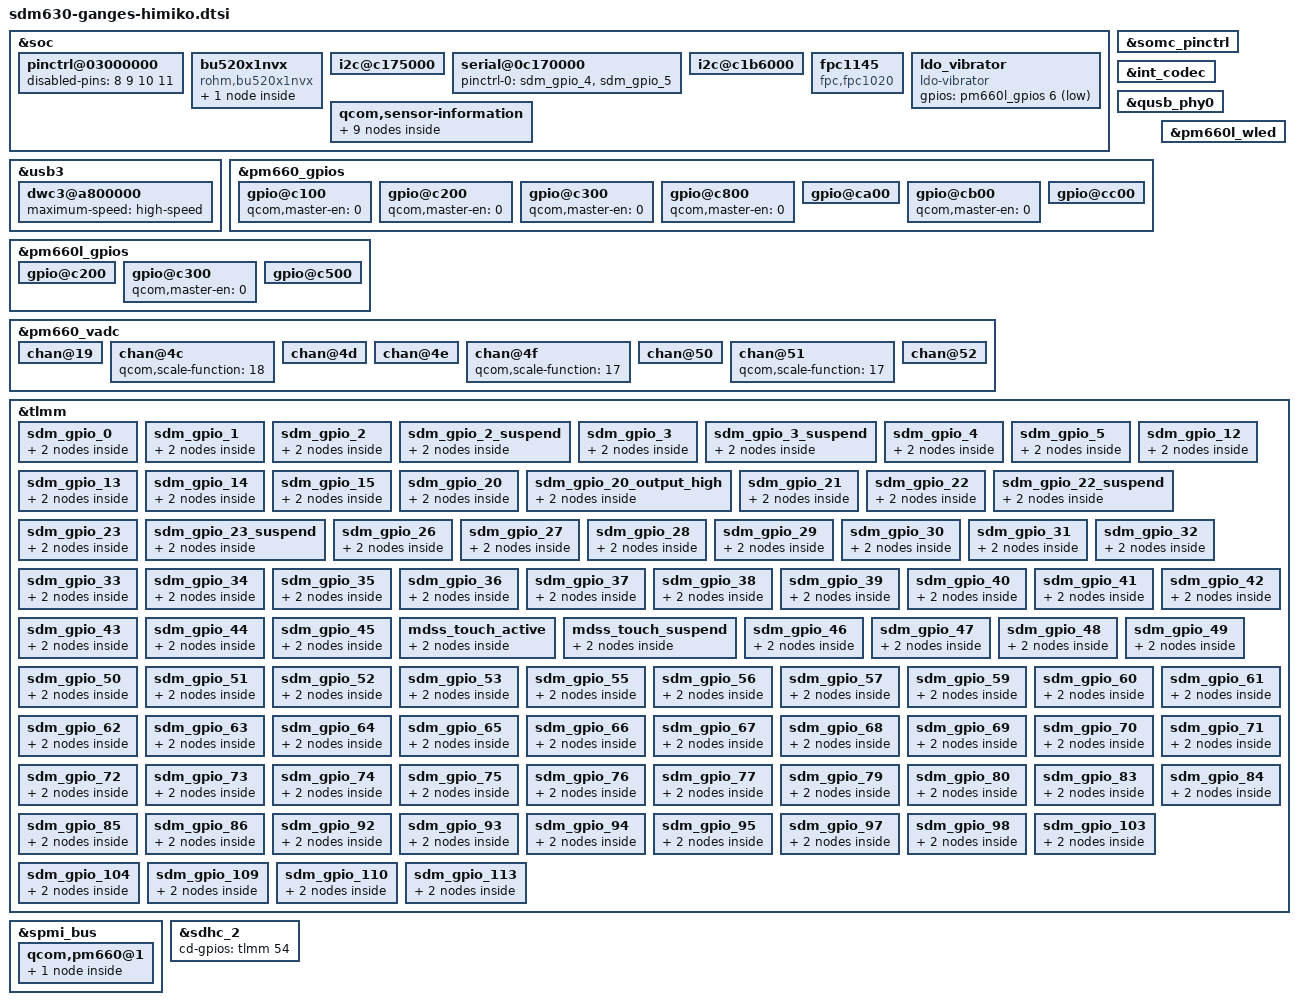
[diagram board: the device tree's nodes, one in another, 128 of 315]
/* arch/arm64/boot/dts/somc/sdm630-ganges-mermaid.dtsi
 *
 * This program is free software; you can redistribute it and/or modify
 * it under the terms of the GNU General Public License version 2 and
 * only version 2 as published by the Free Software Foundation.
 *
 * This program is distributed in the hope that it will be useful,
 * but WITHOUT ANY WARRANTY; without even the implied warranty of
 * MERCHANTABILITY or FITNESS FOR A PARTICULAR PURPOSE.  See the
 * GNU General Public License for more details.
*/
/*
 * Copyright (C) 2018 Sony Mobile Communications Inc.
 *
 * This program is free software; you can redistribute it and/or modify
 * it under the terms of the GNU General Public License version 2, as
 * published by the Free Software Foundation.
 */

#include "sdm630-ganges-common.dtsi"
//#include "sdm630-ganges-mermaid-camera-sensor.dtsi"
#include "sdm630-ganges-himiko-camera-sensor.dtsi"
#include "somc-ganges-nfc_pn81t.dtsi"
#include "dsi-panel-himiko.dtsi"
#include "sdm630-ganges-touch_himiko.dtsi"
#include <dt-bindings/gpio/gpio.h>
#include "charger-ganges-himiko.dtsi"

&soc {
	pinctrl@03000000 {
		disabled-pins = <8 9 10 11>;
	};

	bu520x1nvx {
		compatible = "rohm,bu520x1nvx";

		acc_cover {
			label = "lid";
			gpios = <&tlmm 75 0x1>;
			lid-pin = <1>;
			open-debounce-interval = <120>;
			close-debounce-interval = <300>;
		};
	};

	/* I2C : BLSP1 */
	i2c@c175000 { /* BLSP1 QUP1 */
		pinctrl-0 = <&sdm_gpio_2 &sdm_gpio_3>;
		pinctrl-1 = <&sdm_gpio_2_suspend &sdm_gpio_3_suspend>;
		qcom,clk-freq-out = <400000>;
		status = "okay";
	};

	/* UART : BLSP2 */
	serial@0c170000 {
		pinctrl-0 = <&sdm_gpio_4 &sdm_gpio_5>;
		status = "okay";
	};

	/* I2C : BLSP6 */
	i2c@c1b6000 { /* BLSP2 QUP2 */
		pinctrl-0 = <&sdm_gpio_22 &sdm_gpio_23>;
		pinctrl-1 = <&sdm_gpio_22_suspend &sdm_gpio_23_suspend>;
		qcom,clk-freq-out = <400000>;
		status = "okay";
	};

	fpc1145 {
		status = "ok";
		compatible = "fpc,fpc1020", "fpc1145";
		interrupt-parent = <&tlmm>;
		interrupts = <72 0x0>;
		fpc,gpio_rst    = <&tlmm 20 0x0>;
		fpc,gpio_irq    = <&tlmm 72 0x0>;
		vdd_ana-supply  = <&pm660l_bob>;
		vdd_ana-min-uV  = <3300000>;
		vdd_ana-max-uV  = <3600000>;

		gpio_ldo_enabe = <&pm660l_gpios 3 0x00>;
		pinctrl-names = "fpc1145_reset_reset",
				"fpc1145_reset_active",
				"fpc1145_irq_active";

		pinctrl-0 = <&sdm_gpio_20>;
		pinctrl-1 = <&sdm_gpio_20_output_high>;
		pinctrl-2 = <&sdm_gpio_72>;
	};

	ldo_vibrator {
		compatible = "ldo-vibrator";
		gpios = <&pm660l_gpios 6 1>;
	};
	qcom,sensor-information {
			/* msm_therm */
			sensor_information13: qcom,sensor-information-13 {
				qcom,scaling-factor = <1000>;
			};

			/* xo_therm */
			sensor_information14: qcom,sensor-information-14 {
				qcom,scaling-factor = <1000>;
			};

			/* pa_therm0 */
			sensor_information15: qcom,sensor-information-15 {
				qcom,scaling-factor = <1000>;
			};

			/* pa_therm1 */
			sensor_information16: qcom,sensor-information-16 {
				qcom,scaling-factor = <1000>;
			};

			/* quiet_therm */
			sensor_information17: qcom,sensor-information-17 {
				qcom,scaling-factor = <1000>;
				qcom,alias-name = "bl_therm";
			};

			/* sdm_therm */
			sensor_information100: qcom,sensor-information-100 {
				qcom,sensor-type = "adc";
				qcom,scaling-factor = <1000>;
				qcom,sensor-name = "sdm_therm";
			};

			/* emcp_therm */
			sensor_information101: qcom,sensor-information-101 {
				qcom,sensor-type = "adc";
				qcom,scaling-factor = <1000>;
				qcom,sensor-name = "emcp_therm";
			};

			/* flash_therm */
			sensor_information102: qcom,sensor-information-102 {
				qcom,sensor-type = "adc";
				qcom,sensor-name = "flash_therm";
				qcom,scaling-factor = <1000>;
			};

			/* bms */
			sensor_information103: qcom,sensor-information-103 {
				qcom,sensor-type = "adc";
				qcom,sensor-name = "bms";
				qcom,scaling-factor = <1000>;
				qcom,alias-name = "batt_therm";
			};
		};
};

&somc_pinctrl {
	/* If variant specific default setting is needed,
	fill pinctrl-2 value in <variant>.dtsi */
	pinctrl-2 = <&sdm_gpio_0 &sdm_gpio_1 &sdm_gpio_2 &sdm_gpio_3
			 &sdm_gpio_12 &sdm_gpio_13
			 &sdm_gpio_14 &sdm_gpio_15 &sdm_gpio_20 &sdm_gpio_21 &sdm_gpio_22
			 &sdm_gpio_23 &sdm_gpio_26 &sdm_gpio_27 &sdm_gpio_28 &sdm_gpio_29
			 &sdm_gpio_30 &sdm_gpio_31 &sdm_gpio_32 &sdm_gpio_33 &sdm_gpio_34
			 &sdm_gpio_35 &sdm_gpio_36 &sdm_gpio_37 &sdm_gpio_38 &sdm_gpio_39
			 &sdm_gpio_40 &sdm_gpio_41 &sdm_gpio_42 &sdm_gpio_43 &sdm_gpio_44
			 &sdm_gpio_45 &sdm_gpio_46 &sdm_gpio_47 &sdm_gpio_48 &sdm_gpio_49
			 &sdm_gpio_50 &sdm_gpio_51 &sdm_gpio_52 /*&sdm_gpio_53*/
			 &sdm_gpio_55 &sdm_gpio_56 &sdm_gpio_57 /*&sdm_gpio_59*/ &sdm_gpio_60
			 &sdm_gpio_61 &sdm_gpio_62 &sdm_gpio_63 &sdm_gpio_64 &sdm_gpio_65
			 &sdm_gpio_66 &sdm_gpio_67 &sdm_gpio_68 &sdm_gpio_69 &sdm_gpio_70
			 &sdm_gpio_71 &sdm_gpio_72 &sdm_gpio_73 &sdm_gpio_74 &sdm_gpio_75
			 &sdm_gpio_76 &sdm_gpio_77 &sdm_gpio_79 &sdm_gpio_80
			 &sdm_gpio_83 &sdm_gpio_84 &sdm_gpio_85 &sdm_gpio_86
			 /*&sdm_gpio_90*/ &sdm_gpio_92 &sdm_gpio_93 &sdm_gpio_94 &sdm_gpio_95
			 &sdm_gpio_97 &sdm_gpio_98 &sdm_gpio_103 &sdm_gpio_104
			 &sdm_gpio_109 &sdm_gpio_110 &sdm_gpio_113>;
};

&int_codec {
	qcom,msm-micbias1-ext-cap;
	/delete-property/ qcom,msm-micbias2-ext-cap;
	qcom,msm-hs-micbias-type = "external";
	qcom,audio-routing =
		"RX_BIAS", "INT_MCLK0",
		"SPK_RX_BIAS", "INT_MCLK0",
		"INT_LDO_H", "INT_MCLK0",
		"RX_I2S_CLK", "INT_MCLK0",
		"TX_I2S_CLK", "INT_MCLK0",
		"MIC BIAS External", "Handset Mic",
		"MIC BIAS External2", "Headset Mic",
		"MIC BIAS External", "Secondary Mic",
		"AMIC1", "MIC BIAS External",
		"AMIC2", "MIC BIAS External2",
		"AMIC3", "MIC BIAS External",
		"DMIC1", "MIC BIAS External",
		"MIC BIAS External", "Digital Mic1",
		"DMIC2", "MIC BIAS External",
		"MIC BIAS External", "Digital Mic2",
		"DMIC3", "MIC BIAS External",
		"MIC BIAS External", "Digital Mic3",
		"DMIC4", "MIC BIAS External",
		"MIC BIAS External", "Digital Mic4",
		"SpkrLeft IN", "SPK1 OUT",
		"SpkrRight IN", "SPK2 OUT",
		"PDM_IN_RX1", "PDM_OUT_RX1",
		"PDM_IN_RX2", "PDM_OUT_RX2",
		"PDM_IN_RX3", "PDM_OUT_RX3",
		"ADC1_IN", "ADC1_OUT",
		"ADC2_IN", "ADC2_OUT",
		"ADC3_IN", "ADC3_OUT";
};

&qusb_phy0 {
	qcom,tune2-efuse-correction = <0>;
	qcom,qusb-phy-init-seq = <0xf8 0x80
			0xd3 0x84
			0x83 0x88
			0xc7 0x8c
			0x30 0x08
			0x79 0x0c
			0x21 0x10
			0x14 0x9c
			0x9f 0x1c
			0x00 0x18>;
};

&usb3 {
	dwc3@a800000 {
		maximum-speed = "high-speed";
	};
};

&pm660_gpios {
	/* GPIO_1: PON_OPTION_1 */
	/* Follow QTI */

	/* GPIO_2: FLASH_THERM */
	gpio@c100 {
		qcom,master-en = <0>;           /* Disable */
		status = "okay";
	};

	/* GPIO_3: LCD_ID */
	gpio@c200 {
		qcom,master-en = <0>;           /* Disable */
		status = "okay";
	};

	/* GPIO_4: NFC_CLK_REQ */
	gpio@c300 {
		qcom,master-en = <0>;           /* Disable */
		status = "okay";
	};

	/* GPIO_5: WLAN_SW_CTRL */
	/* Follow QTI */

	/* GPIO_6: PMK_SLEEP_CLK */
	/* Follow QTI */

	/* GPIO_7: BUA */
	/* Follow QTI */

	/* GPIO_8: SLB */
	/* Follow QTI */

	/* GPIO_9: NC */
	gpio@c800 {
		qcom,master-en = <0>;           /* Disable */
		status = "okay";
	};

	/* GPIO_10: WCSS_PWR_REQ */
	/* Follow QTI */

	/* GPIO_11: RF_ID_0 */
	gpio@ca00 {
		qcom,src-sel = <0>;             /* GPIO */
		qcom,mode = <0>;                /* In */
		qcom,vin-sel = <0>;             /* 1.8V */
		qcom,pull = <4>;		/* PD */
		qcom,master-en = <1>;           /* Enable */
		status = "ok";
	};

	/* GPIO_12: USB_DETECT_ADC */
	gpio@cb00 {
		qcom,master-en = <0>;           /* Disable */
		status = "okay";
	};

	/* GPIO_13: RF_ID_1 */
	gpio@cc00 {
		qcom,src-sel = <0>;             /* GPIO */
		qcom,mode = <0>;                /* In */
		qcom,vin-sel = <0>;             /* 1.8V */
		qcom,pull = <4>;		/* PD */
		qcom,master-en = <1>;           /* Enable */
		status = "ok";
	};
};

&pm660l_gpios {
	/* GPIO_1: GPIO_1B */
	/* Follow QTI */

	/* GPIO_2: LPI_PWR_EN */
	/* Follow QTI */

	/* GPIO_3: FP_LDO_EN */
	gpio@c200 {
		qcom,mode = <1>;                /* Output */
		qcom,pull = <5>;                /* No Pull */
		qcom,vin-sel = <0>;             /* VIN1 GPIO_LV */
		qcom,src-sel = <0>;             /* GPIO */
		qcom,master-en = <1>;           /* Enable GPIO */
		status = "ok";
	};

	/* GPIO_4: NC */
	gpio@c300 {
		qcom,master-en = <0>;           /* Disable */
		status = "okay";
	};

	/* GPIO_5: NC */
	/* Follow QTI */

	/* GPIO_6: VIB_LDO_EN */
	gpio@c500 {
		qcom,src-sel = <0>;             /* GPIO */
		qcom,mode = <1>;                /* Out */
		qcom,output-type = <0>;         /* CMOS */
		qcom,vin-sel = <0>;             /* 1.8V */
		qcom,out-strength = <1>;        /* Low */
		qcom,invert = <0>;              /* Low */
		qcom,master-en = <1>;           /* Enable */
		status = "okay";
	};

	/* GPIO_7: VOL_DN_S */
	/* Follow QTI */

	/* GPIO_8: NC */
	/* Follow QTI */

	/* GPIO_9: WCSS_PWR_REQ */
	/* Follow QTI */

	/* GPIO_10: SLB */
	/* Follow QTI */

	/* GPIO_11: LP4X_CTRL_BUCK_EN */
	/* Follow QTI */

	/* GPIO_12: LP4X_BUCK_MODE */
	/* Follow QTI */
};
&pm660_vadc {
	chan@19 { /* USB_DETECT_ADC */
		label = "usb_detect";
		reg = <0x19>;
		qcom,decimation = <0>;
		qcom,pre-div-channel-scaling = <0>;
		qcom,calibration-type = "absolute";
		qcom,scale-function = <0>;
		qcom,hw-settle-time = <5>;
		qcom,fast-avg-setup = <0>;
	};

	chan@4c { /* XO_THERM */
		qcom,scale-function = <18>;
	};

	chan@4d { /* Rename from msm_therm */
		label = "sdm_therm";
		qcom,scale-function = <17>;
		qcom,vadc-thermal-node;
	};

	chan@4e { /* Rename from emmc_therm */
		label = "emcp_therm";
		qcom,scale-function = <17>;
	};

	chan@4f { /* pa_therm0 */
		qcom,scale-function = <17>;
	};

	chan@50 {
		label = "pa_therm1";
		reg = <0x50>;
		qcom,decimation = <2>;
		qcom,pre-div-channel-scaling = <0>;
		qcom,calibration-type = "ratiometric";
		qcom,scale-function = <17>;
		qcom,hw-settle-time = <2>;
		qcom,fast-avg-setup = <0>;
		qcom,vadc-thermal-node;
	};

	chan@51 { /* quiet_therm */
		qcom,scale-function = <17>;
	};

	chan@52 {
		label = "flash_therm";
		reg = <0x52>;
		qcom,decimation = <2>;
		qcom,pre-div-channel-scaling = <0>;
		qcom,calibration-type = "ratiometric";
		qcom,scale-function = <17>;
		qcom,hw-settle-time = <2>;
		qcom,fast-avg-setup = <0>;
		qcom,vadc-thermal-node;
	};
};
&pm660l_wled {
	qcom,led-strings-list = [00 01 02];
	qcom,fs-curr-ua = <21000>;
	somc,calc-curr;
};

&tlmm {
	/* GPIO_0 : HWID_1 */
	sdm_gpio_0: sdm_gpio_0 {
		mux {
			pins = "gpio0";
			function = "gpio";
		};

		config {
			pins = "gpio0";
			drive-strength = <2>;
			bias-disable;
			input-enable;
		};
	};

	/* GPIO_1 : HWID_2 */
	sdm_gpio_1: sdm_gpio_1 {
		mux {
			pins = "gpio1";
			function = "gpio";
		};

		config {
			pins = "gpio1";
			drive-strength = <2>;
			bias-disable;
			input-enable;
		};
	};

	/* GPIO_2 : BLSP4_I2C_SDA */
	sdm_gpio_2: sdm_gpio_2 {
		mux {
			pins = "gpio2";
			function = "blsp_i2c1";
		};

		config {
			pins = "gpio2";
			drive-strength = <2>;
			bias-disable;
		};
	};

	/* GPIO_2 : BLSP4_I2C_SDA (Suspend) */
	sdm_gpio_2_suspend: sdm_gpio_2_suspend {
		mux {
			pins = "gpio2";
			function = "gpio";
		};

		config {
			pins = "gpio2";
			drive-strength = <2>;
			bias-disable;
			input-enable;
		};
	};

	/* GPIO_3 : BLSP1_I2C_SCL */
	sdm_gpio_3: sdm_gpio_3 {
		mux {
			pins = "gpio3";
			function = "blsp_i2c1";
		};

		config {
			pins = "gpio3";
			drive-strength = <2>;
			bias-disable;
		};
	};

	/* GPIO_3 : BLSP1_I2C_SCL (Suspend) */
	sdm_gpio_3_suspend: sdm_gpio_3_suspend {
		mux {
			pins = "gpio3";
			function = "gpio";
		};

		config {
			pins = "gpio3";
			drive-strength = <2>;
			bias-disable;
			input-enable;
		};
	};

	/* GPIO_4 : BLSP2_UART_TX */
	sdm_gpio_4: sdm_gpio_4 {
		mux {
			pins = "gpio4";
			function = "blsp_uart2";
		};

		config {
			pins = "gpio4";
			drive-strength = <4>;
			bias-disable;
		};
	};

	/* GPIO_5 : BLSP2_UART_RX */
	sdm_gpio_5: sdm_gpio_5 {
		mux {
			pins = "gpio5";
			function = "blsp_uart2";
		};

		config {
			pins = "gpio5";
			drive-strength = <2>;
			bias-pull-up;
		};
	};

	/* GPIO_6 : BLSP2_I2C_SDA */
	/* Follow QTI */

	/* GPIO_7 : BLSP2_I2C_SCL */
	/* Follow QTI */

	/* GPIO_12 : NFC_ESE_SPI_MOSI */
	sdm_gpio_12: sdm_gpio_12 {
		mux {
			pins = "gpio12";
			function = "blsp_spi4";
		};

		config {
			pins = "gpio12";
			drive-strength = <6>;
			bias-pull-down;
		};
	};

	/* GPIO_13 : NFC_ESE_SPI_MISO */
	sdm_gpio_13: sdm_gpio_13 {
		mux {
			pins = "gpio13";
			function = "blsp_spi4";
		};

		config {
			pins = "gpio13";
			drive-strength = <2>;
			bias-disable;
		};
	};

	/* GPIO_14 : NFC_ESE_SPI_CS_N */
	sdm_gpio_14: sdm_gpio_14 {
		mux {
			pins = "gpio14";
			function = "gpio";
		};

		config {
			pins = "gpio14";
			drive-strength = <2>;
			bias-disable;
			output-low;
		};
	};

	/* GPIO_15 : NFC_ESE_SPI_SCLK */
	sdm_gpio_15: sdm_gpio_15 {
		mux {
			pins = "gpio15";
			function = "blsp_spi4";
		};

		config {
			pins = "gpio15";
			drive-strength = <6>;
			bias-pull-down;
		};
	};

	/* GPIO_16 : BLSP5_HCI_UART_TX */
	/* Follow QTI */

	/* GPIO_17 : BLSP5_HCI_UART_RX */
	/* Follow QTI */

	/* GPIO_18 : BLSP5_HCI_UART_CTS_N */
	/* Follow QTI */

	/* GPIO_19 : BLSP5_HCI_UART_RFR_N */
	/* Follow QTI */

	/* GPIO_20 : FP_RESET_N */
	sdm_gpio_20: sdm_gpio_20 {
		mux {
			pins = "gpio20";
			function = "gpio";
		};

		config {
			pins = "gpio20";
			drive-strength = <2>;
			bias-disable;
			output-low;
		};
	};

	/* GPIO_20 : FP_RESET_N, state device active */
	sdm_gpio_20_output_high: sdm_gpio_20_output_high {
		mux {
			pins = "gpio20";
			function = "gpio";
		};

		config {
			pins = "gpio20";
			drive-strength = <2>;
			bias-disable;
			output-high;
		};
	};

	/* GPIO_21 : SUBC_AFVDD_EN */
	sdm_gpio_21: sdm_gpio_21 {
		mux {
			pins = "gpio21";
			function = "gpio";
		};

		config {
			pins = "gpio21";
			drive-strength = <2>;
			bias-disable;
			output-low;
		};
	};

	/* GPIO_22 : BLSP6_I2C_SDA */
	sdm_gpio_22: sdm_gpio_22 {
		mux {
			pins = "gpio22";
			function = "blsp_i2c6";
		};

		config {
			pins = "gpio22";
			drive-strength = <2>;
			bias-disable;
		};
	};

	/* GPIO_22 : BLSP6_I2C_SDA (Suspend) */
	sdm_gpio_22_suspend: sdm_gpio_22_suspend {
		mux {
			pins = "gpio22";
			function = "gpio";
		};

		config {
			pins = "gpio22";
			drive-strength = <2>;
			bias-pull-up;
			input-enable;
		};
	};

	/* GPIO_23 : BLSP6_I2C_SCL */
	sdm_gpio_23: sdm_gpio_23 {
		mux {
			pins = "gpio23";
			function = "blsp_i2c6";
		};

		config {
			pins = "gpio23";
			drive-strength = <2>;
			bias-disable;
		};
	};

	/* GPIO_23 : BLSP6_I2C_SCL (Suspend) */
	sdm_gpio_23_suspend: sdm_gpio_23_suspend {
		mux {
			pins = "gpio23";
			function = "gpio";
		};

		config {
			pins = "gpio23";
			drive-strength = <2>;
			bias-pull-up;
			input-enable;
		};
	};

	/* GPIO_24 : SDM_SWR_CLK */
	/* Follow QTI */

	/* GPIO_25 : SDM_SWR_DATA */
	/* Follow QTI */

	/* GPIO_26 : WSA_EN */
	sdm_gpio_26: sdm_gpio_26 {
		mux {
			pins = "gpio26";
			function = "gpio";
		};

		config {
			pins = "gpio26";
			drive-strength = <2>;
			bias-disable;
			output-low;
		};
	};

	/* GPIO_27 : NC */
	sdm_gpio_27: sdm_gpio_27 {
		mux {
			pins = "gpio27";
			function = "gpio";
		};

		config {
			pins = "gpio27";
			drive-strength = <2>;
			bias-pull-down;
			input-enable;
		};
	};

	/* GPIO_28 : NFC_IRQ */
	sdm_gpio_28: sdm_gpio_28 {
		mux {
			pins = "gpio28";
			function = "gpio";
		};

		config {
			pins = "gpio28";
			drive-strength = <2>;
			bias-pull-down;
			input-enable;
		};
	};

	/* GPIO_29 : NFC_EN */
	sdm_gpio_29: sdm_gpio_29 {
		mux {
			pins = "gpio29";
			function = "gpio";
		};

		config {
			pins = "gpio29";
			drive-strength = <2>;
			bias-disable;
			output-low;
		};
	};

	/* GPIO_30 : NFC_DWL_REQ */
	sdm_gpio_30: sdm_gpio_30 {
		mux {
			pins = "gpio30";
			function = "gpio";
		};

		config {
			pins = "gpio30";
			drive-strength = <2>;
			bias-disable;
			output-low;
		};
	};

	/* GPIO_31 : NFC_ESE_PWR_REQ */
	sdm_gpio_31: sdm_gpio_31 {
		mux {
			pins = "gpio31";
			function = "gpio";
		};

		config {
			pins = "gpio31";
			drive-strength = <2>;
			bias-disable;
			output-low;
		};
	};

	/* GPIO_32 : CAM0_MCLK */
	sdm_gpio_32: sdm_gpio_32 {
		mux {
			pins = "gpio32";
			function = "cam_mclk";
		};

		config {
			pins = "gpio32";
			drive-strength = <2>;
			bias-disable;
		};
	};

	/* GPIO_33 : CAM2_MCLK */
	sdm_gpio_33: sdm_gpio_33 {
		mux {
			pins = "gpio33";
			function = "cam_mclk";
		};

		config {
			pins = "gpio33";
			drive-strength = <2>;
			bias-disable;
		};
	};

	/* GPIO_34 : T2_MODE */
	sdm_gpio_34: sdm_gpio_34 {
		mux {
			pins = "gpio34";
			function = "gpio";
		};

		config {
			pins = "gpio34";
			drive-strength = <2>;
			bias-disable;
			output-low;
		};
	};

	/* GPIO_35 : CAM1_MCLK */
	sdm_gpio_35: sdm_gpio_35 {
		mux {
			pins = "gpio35";
			function = "cam_mclk";
		};

		config {
			pins = "gpio35";
			drive-strength = <2>;
			bias-disable;
			output-low;
		};
	};

	/* GPIO_36 : CCI_I2C_SDA0 */
	sdm_gpio_36: sdm_gpio_36 {
		mux {
			pins = "gpio36";
			function = "cci_i2c";
		};

		config {
			pins = "gpio36";
			drive-strength = <2>;
			bias-disable;
		};
	};

	/* GPIO_37 : CCI_I2C_SCL0 */
	sdm_gpio_37: sdm_gpio_37 {
		mux {
			pins = "gpio37";
			function = "cci_i2c";
		};

		config {
			pins = "gpio37";
			drive-strength = <2>;
			bias-disable;
		};
	};

	/* GPIO_38 : CCI_I2C_SDA1 */
	sdm_gpio_38: sdm_gpio_38 {
		mux {
			pins = "gpio38";
			function = "cci_i2c";
		};

		config {
			pins = "gpio38";
			drive-strength = <2>;
			bias-disable;
		};
	};

	/* GPIO_39 : CCI_I2C_SCL1 */
	sdm_gpio_39: sdm_gpio_39 {
		mux {
			pins = "gpio39";
			function = "cci_i2c";
		};

		config {
			pins = "gpio39";
			drive-strength = <2>;
			bias-disable;
		};
	};

	/* GPIO_40 : MAIN_DVDD_EN */
	sdm_gpio_40: sdm_gpio_40 {
		mux {
			pins = "gpio40";
			function = "gpio";
		};

		config {
			pins = "gpio40";
			drive-strength = <2>;
			bias-disable;
			output-low;
		};
	};

	/* GPIO_41 : FL_STROBE_TRIG */
	sdm_gpio_41: sdm_gpio_41 {
		mux {
			pins = "gpio41";
			function = "gpio";
		};

		config {
			pins = "gpio41";
			drive-strength = <2>;
			bias-disable;
			output-low;
		};
	};

	/* GPIO_42 : CAM1_RST_N */
	sdm_gpio_42: sdm_gpio_42 {
		mux {
			pins = "gpio42";
			function = "gpio";
		};

		config {
			pins = "gpio42";
			drive-strength = <2>;
			bias-disable;
			output-low;
		};
	};

	/* GPIO_43 : NC */
	sdm_gpio_43: sdm_gpio_43 {
		mux {
			pins = "gpio43";
			function = "gpio";
		};

		config {
			pins = "gpio43";
			drive-strength = <2>;
			bias-pull-down;
			input-enable;
		};
	};

	/* GPIO_44 : SUB_8M_ID */
	sdm_gpio_44: sdm_gpio_44 {
		mux {
			pins = "gpio44";
			function = "gpio";
		};

		config {
			pins = "gpio44";
			drive-strength = <2>;
			bias-disable;
			output-low;
		};
	};

	/* GPIO_45 : TS_INT_N */
	sdm_gpio_45: sdm_gpio_45 {
		mux {
			pins = "gpio45";
			function = "gpio";
		};

		config {
			pins = "gpio45";
			drive-strength = <2>;
			bias-pull-down;
			input-enable;
		};
	};

	mdss_touch_active: mdss_touch_active {
		mux {
			pins = "gpio45";
			function = "gpio";
		};

		config {
			pins = "gpio45";
			drive-strength = <2>;
			bias-pull-up;
		};
	};

	mdss_touch_suspend: mdss_touch_suspend {
		mux {
			pins = "gpio45";
			function = "gpio";
		};

		config {
			pins = "gpio45";
			drive-strength = <2>;
			bias-pull-down;
		};
	};

	/* GPIO_46 : CAM0_RST_N */
	sdm_gpio_46: sdm_gpio_46 {
		mux {
			pins = "gpio46";
			function = "gpio";
		};

		config {
			pins = "gpio46";
			drive-strength = <2>;
			bias-disable;
			output-low;
		};
	};

	/* GPIO_47 : CAM2_RST_N */
	sdm_gpio_47: sdm_gpio_47 {
		mux {
			pins = "gpio47";
			function = "gpio";
		};

		config {
			pins = "gpio47";
			drive-strength = <2>;
			bias-disable;
			output-low;
		};
	};

	/* GPIO_48 : SW_SERVICE */
	sdm_gpio_48: sdm_gpio_48 {
		mux {
			pins = "gpio48";
			function = "gpio";
		};

		config {
			pins = "gpio48";
			drive-strength = <2>;
			bias-pull-up;
			input-enable;
		};
	};

	/* GPIO_49 : FRONT_8M_ID */
	sdm_gpio_49: sdm_gpio_49 {
		mux {
			pins = "gpio49";
			function = "gpio";
		};

		config {
			pins = "gpio49";
			drive-strength = <2>;
			bias-disable;
			output-low;
		};
	};

	/* GPIO_50 : MAINC_AVDD_EN */
	sdm_gpio_50: sdm_gpio_50 {
		mux {
			pins = "gpio50";
			function = "gpio";
		};

		config {
			pins = "gpio50";
			drive-strength = <2>;
			bias-disable;
			output-low;
		};
	};

	/* GPIO_51 : SUBC_CHATC_AVDD_EN */
	sdm_gpio_51: sdm_gpio_51 {
		mux {
			pins = "gpio51";
			function = "gpio";
		};

		config {
			pins = "gpio51";
			drive-strength = <2>;
			bias-disable;
			output-low;
		};
	};

	/* GPIO_52 : SUBC_CHATC_DVDD_EN */
	sdm_gpio_52: sdm_gpio_52 {
		mux {
			pins = "gpio52";
			function = "gpio";
		};

		config {
			pins = "gpio52";
			drive-strength = <2>;
			bias-disable;
			output-low;
		};
	};

	/* GPIO_53 : LCD_RST_N */
	sdm_gpio_53: sdm_gpio_53 {
		mux {
			pins = "gpio53";
			function = "gpio";
		};

		config {
			pins = "gpio53";
			drive-strength = <2>;
			bias-disable;
		};
	};

	/* GPIO_54 : TRAY2_DET */
	/* Follow QTI */

	/* GPIO_55 : RF_LCD_ID_EN */
	sdm_gpio_55: sdm_gpio_55 {
		mux {
			pins = "gpio55";
			function = "gpio";
		};

		config {
			pins = "gpio55";
			drive-strength = <2>;
			bias-disable;
			output-low;
		};
	};

	/* GPIO_56 : NC */
	sdm_gpio_56: sdm_gpio_56 {
		mux {
			pins = "gpio56";
			function = "gpio";
		};

		config {
			pins = "gpio56";
			drive-strength = <2>;
			bias-pull-down;
			input-enable;
		};
	};

	/* GPIO_57 : FORCED_USB_BOOT */
	sdm_gpio_57: sdm_gpio_57 {
		mux {
			pins = "gpio57";
			function = "gpio";
		};

		config {
			pins = "gpio57";
			drive-strength = <2>;
			bias-pull-down;
			input-enable;
		};
	};

	/* GPIO_58 : USB_PHY_PS */
	/* Follow QTI */

	/* GPIO_59 : MDP_VSYNC_P */
	sdm_gpio_59: sdm_gpio_59 {
		mux {
			pins = "gpio59";
			function = "mdp_vsync";
		};

		config {
			pins = "gpio59";
			drive-strength = <2>;
			bias-disable;
		};
	};

	/* GPIO_60 : NC */
	sdm_gpio_60: sdm_gpio_60 {
		mux {
			pins = "gpio60";
			function = "gpio";
		};

		config {
			pins = "gpio60";
			drive-strength = <2>;
			bias-pull-down;
			input-enable;
		};
	};

	/* GPIO_61 : USB_DETECT_EN */
	sdm_gpio_61: sdm_gpio_61 {
		mux {
			pins = "gpio61";
			function = "gpio";
		};

		config {
			pins = "gpio61";
			drive-strength = <2>;
			bias-disable;
			output-low;
		};
	};

	/* GPIO_62 : DEBUG_GPIO0 */
	sdm_gpio_62: sdm_gpio_62 {
		mux {
			pins = "gpio62";
			function = "gpio";
		};

		config {
			pins = "gpio62";
			drive-strength = <2>;
			bias-disable;
			output-low;
		};
	};

	/* GPIO_63 : CAM_IO_EN */
	sdm_gpio_63: sdm_gpio_63 {
		mux {
			pins = "gpio63";
			function = "gpio";
		};

		config {
			pins = "gpio63";
			drive-strength = <2>;
			bias-disable;
			output-low;
		};
	};

	/* GPIO_64 : NC */
	sdm_gpio_64: sdm_gpio_64 {
		mux {
			pins = "gpio64";
			function = "gpio";
		};

		config {
			pins = "gpio64";
			drive-strength = <2>;
			bias-pull-down;
			input-enable;
		};
	};

	/* GPIO_65 : NC */
	sdm_gpio_65: sdm_gpio_65 {
		mux {
			pins = "gpio65";
			function = "gpio";
		};

		config {
			pins = "gpio65";
			drive-strength = <2>;
			bias-pull-down;
			input-enable;
		};
	};

	/* GPIO_66 : TS_RESET_N */
	sdm_gpio_66: sdm_gpio_66 {
		mux {
			pins = "gpio66";
			function = "gpio";
		};

		config {
			pins = "gpio66";
			drive-strength = <2>;
			bias-disable;
			output-low;
		};
	};

	/* GPIO_67 : PA_INDICATOR_IN */
	sdm_gpio_67: sdm_gpio_67 {
		mux {
			pins = "gpio67";
			function = "gpio";
		};

		config {
			pins = "gpio67";
			drive-strength = <2>;
			bias-disable;
			input-enable;
		};
	};

	/* GPIO_68 : ACCEL_INT */
	sdm_gpio_68: sdm_gpio_68 {
		mux {
			pins = "gpio68";
			function = "gpio";
		};

		config {
			pins = "gpio68";
			drive-strength = <2>;
			bias-disable;
			input-enable;
		};
	};

	/* GPIO_69 : GYRO_INT */
	sdm_gpio_69: sdm_gpio_69 {
		mux {
			pins = "gpio69";
			function = "gpio";
		};

		config {
			pins = "gpio69";
			drive-strength = <2>;
			bias-disable;
			input-enable;
		};
	};

	/* GPIO_70 : NC */
	sdm_gpio_70: sdm_gpio_70 {
		mux {
			pins = "gpio70";
			function = "gpio";
		};

		config {
			pins = "gpio70";
			drive-strength = <2>;
			bias-pull-down;
			input-enable;
		};
	};

	/* GPIO_71 : ALPS_INT_N */
	sdm_gpio_71: sdm_gpio_71 {
		mux {
			pins = "gpio71";
			function = "gpio";
		};

		config {
			pins = "gpio71";
			drive-strength = <2>;
			bias-disable;
			input-enable;
		};
	};


	/* GPIO_72 : FP_SDM_INT_N */
	sdm_gpio_72: sdm_gpio_72 {
		mux {
			pins = "gpio72";
			function = "gpio";
		};

		config {
			pins = "gpio72";
			drive-strength = <2>;
			bias-pull-down;
			input-enable;
		};
	};

	/* GPIO_73 : BAROMETER_INT */
	sdm_gpio_73: sdm_gpio_73 {
		mux {
			pins = "gpio73";
			function = "gpio";
		};

		config {
			pins = "gpio73";
			drive-strength = <2>;
			bias-disable;
			input-enable;
		};
	};

	/* GPIO_74 : DEBUG_GPIO1 */
	sdm_gpio_74: sdm_gpio_74 {
		mux {
			pins = "gpio74";
			function = "gpio";
		};

		config {
			pins = "gpio74";
			drive-strength = <2>;
			bias-disable;
			output-low;
		};
	};

	/* GPIO_75 : HALL_INT_N */
	sdm_gpio_75: sdm_gpio_75 {
		mux {
			pins = "gpio75";
			function = "gpio";
		};

		config {
			pins = "gpio75";
			drive-strength = <2>;
			bias-disable;
			input-enable;
		};
	};

	/* GPIO_76 : EINT_RAMDUMP */
	sdm_gpio_76: sdm_gpio_76 {
		mux {
			pins = "gpio76";
			function = "gpio";
		};

		config {
			pins = "gpio76";
			drive-strength = <2>;
			bias-pull-down;
			input-enable;
		};
	};

	/* GPIO_77 : N_FTM_EN */
	sdm_gpio_77: sdm_gpio_77 {
		mux {
			pins = "gpio77";
			function = "gpio";
		};

		config {
			pins = "gpio77";
			drive-strength = <2>;
			bias-pull-down;
			input-enable;
		};
	};

	/* GPIO_78 : WMSS_RST_N */
	/* Follow QTI */

	/* GPIO_79 : NC */
	sdm_gpio_79: sdm_gpio_79 {
		mux {
			pins = "gpio79";
			function = "gpio";
		};

		config {
			pins = "gpio79";
			drive-strength = <2>;
			bias-pull-down;
			input-enable;
		};
	};

	/* GPIO_80 : SDM_GPIO_80 */
	sdm_gpio_80: sdm_gpio_80 {
		mux {
			pins = "gpio80";
			function = "gpio";
		};

		config {
			pins = "gpio80";
			drive-strength = <2>;
			bias-disable;
			input-enable;
		};
	};

	/* GPIO_81 : MSS_LTE_COEX_TX */
	/* Follow QTI */

	/* GPIO_82 : MSS_LTE_COEX_RX */
	/* Follow QTI */

	/* GPIO_83 : NC */
	sdm_gpio_83: sdm_gpio_83 {
		mux {
			pins = "gpio83";
			function = "gpio";
		};

		config {
			pins = "gpio83";
			drive-strength = <2>;
			bias-pull-down;
			input-enable;
		};
	};

	/* GPIO_84 : NC */
	sdm_gpio_84: sdm_gpio_84 {
		mux {
			pins = "gpio84";
			function = "gpio";
		};

		config {
			pins = "gpio84";
			drive-strength = <2>;
			bias-pull-down;
			input-enable;
		};
	};

	/* GPIO_85 : NC */
	sdm_gpio_85: sdm_gpio_85 {
		mux {
			pins = "gpio85";
			function = "gpio";
		};

		config {
			pins = "gpio85";
			drive-strength = <2>;
			bias-pull-down;
			input-enable;
		};
	};

	/* GPIO_86 : NC */
	sdm_gpio_86: sdm_gpio_86 {
		mux {
			pins = "gpio86";
			function = "gpio";
		};

		config {
			pins = "gpio86";
			drive-strength = <2>;
			bias-pull-down;
			input-enable;
		};
	};

	/* GPIO_87 : UIM1_DATA */
	/* Follow QTI */

	/* GPIO_88 : UIM1_CLK */
	/* Follow QTI */

	/* GPIO_89 : UIM1_RESET */
	/* Follow QTI */

	/* GPIO_90 : UIM1_PRESENT */
	/*
	 * already set by sdm630-ganges-common.dtsi
	 */
	/*
	sdm_gpio_90: sdm_gpio_90 {
		mux {
			pins = "gpio90";
			function = "gpio";
		};

		config {
			pins = "gpio90";
			drive-strength = <2>;
			bias-disable;
			input-enable;
		};
	};
	*/

	/* GPIO_91 : BUA */
	/* Follow QTI */

	/* GPIO_92 : PA_INDICATOR_OUT */
	sdm_gpio_92: sdm_gpio_92 {
		mux {
			pins = "gpio92";
			function = "pa_indicator";
		};

		config {
			pins = "gpio92";
			drive-strength = <2>;
			bias-disable;
			output-low;
		};
	};

	/* GPIO_93 : NC */
	sdm_gpio_93: sdm_gpio_93 {
		mux {
			pins = "gpio93";
			function = "gpio";
		};

		config {
			pins = "gpio93";
			drive-strength = <2>;
			bias-pull-down;
			input-enable;
		};
	};

	/* GPIO_94 : NC */
	sdm_gpio_94: sdm_gpio_94 {
		mux {
			pins = "gpio94";
			function = "gpio";
		};

		config {
			pins = "gpio94";
			drive-strength = <2>;
			bias-pull-down;
			input-enable;
		};
	};

	/* GPIO_95 : NC */
	sdm_gpio_95: sdm_gpio_95 {
		mux {
			pins = "gpio95";
			function = "gpio";
		};

		config {
			pins = "gpio95";
			drive-strength = <2>;
			bias-pull-down;
			input-enable;
		};
	};

	/* GPIO_96 : ANT_GPIO_E */
	/* Follow QTI */

	/* GPIO_97 : NC */
	sdm_gpio_97: sdm_gpio_97 {
		mux {
			pins = "gpio97";
			function = "gpio";
		};

		config {
			pins = "gpio97";
			drive-strength = <2>;
			bias-pull-down;
			input-enable;
		};
	};

	/* GPIO_98 : NC */
	sdm_gpio_98: sdm_gpio_98 {
		mux {
			pins = "gpio98";
			function = "gpio";
		};

		config {
			pins = "gpio98";
			drive-strength = <2>;
			bias-pull-down;
			input-enable;
		};
	};

	/* GPIO_99 : QLINK_REQUEST */
	/* Follow QTI */

	/* GPIO_100 : QLINK_ENABLE */
	/* Follow QTI */

	/* GPIO_101 : RFFE1_DATA */
	/* Follow QTI */

	/* GPIO_102 : RFFE1_CLK */
	/* Follow QTI */

	/* GPIO_103 : NC */
	sdm_gpio_103: sdm_gpio_103 {
		mux {
			pins = "gpio103";
			function = "gpio";
		};

		config {
			pins = "gpio103";
			drive-strength = <2>;
			bias-pull-down;
			input-enable;
		};
	};

	/* GPIO_104 : NC */
	sdm_gpio_104: sdm_gpio_104 {
		mux {
			pins = "gpio104";
			function = "gpio";
		};

		config {
			pins = "gpio104";
			drive-strength = <2>;
			bias-pull-down;
			input-enable;
		};
	};

	/* GPIO_105 : RFFE3_DATA */
	/* Follow QTI */

	/* GPIO_106 : RFFE3_CLK */
	/* Follow QTI */

	/* GPIO_107 : RFFE4_DATA */
	/* Follow QTI */

	/* GPIO_108 : RFFE4_CLK */
	/* Follow QTI */

	/* GPIO_109 : NC */
	sdm_gpio_109: sdm_gpio_109 {
		mux {
			pins = "gpio109";
			function = "gpio";
		};

		config {
			pins = "gpio109";
			drive-strength = <2>;
			bias-pull-down;
			input-enable;
		};
	};

	/* GPIO_110 : NC */
	sdm_gpio_110: sdm_gpio_110 {
		mux {
			pins = "gpio110";
			function = "gpio";
		};

		config {
			pins = "gpio110";
			drive-strength = <2>;
			bias-pull-down;
			input-enable;
		};
	};

	/* GPIO_111 : RFFE6_DATA */
	/* Follow QTI */

	/* GPIO_112 : RFFE6_CLK */
	/* Follow QTI */

	/* GPIO_113 : NC */
	sdm_gpio_113: sdm_gpio_113 {
		mux {
			pins = "gpio113";
			function = "gpio";
		};

		config {
			pins = "gpio113";
			drive-strength = <2>;
			bias-pull-down;
			input-enable;
		};
	};
};

&spmi_bus {
	qcom,pm660@1 {
		pm660_haptics: qcom,haptic@c000 {
			qcom,actuator-type = "erm";
			qcom,vmax-mv = <3000>;
		};
	};
};

&usb3 {
	id_polling_use;
	id_polling_up_interval = <2000>;
	id_polling_up_period = <0>;
	id_polling_pd_gpio = <&tlmm 61 0>;
	qcom,usb_detect-vadc = <&pm660_vadc>;
};

&sdhc_2 {
	cd-gpios = <&tlmm 54 0x0>;
};

&pm660_vadc {
	chan@50 {
		label = "pa_therm1";
		reg = <0x50>;
		qcom,decimation = <2>;
		qcom,pre-div-channel-scaling = <0>;
		qcom,calibration-type = "ratiometric";
		qcom,scale-function = <17>;
		qcom,hw-settle-time = <2>;
		qcom,fast-avg-setup = <0>;
		qcom,vadc-thermal-node;
	};

	chan@51 { /* quiet_therm */
		qcom,scale-function = <17>;
	};

	chan@4e { /* emmc_therm */
		qcom,scale-function = <17>;
	};

	chan@4f { /* pa_therm0 */
		qcom,scale-function = <17>;
	};

	chan@4d { /* msm_therm */
		qcom,scale-function = <17>;
	};

	chan@4c { /* xo_therm */
		qcom,scale-function = <18>;
	};
};
